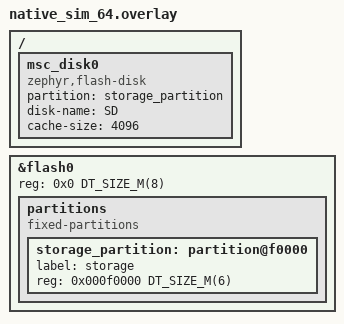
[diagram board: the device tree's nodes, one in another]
/*
 * Copyright (c) 2023 Nordic Semiconductor ASA
 * Copyright (c) 2025 Muhammad Waleed Badar
 * Copyright 2026 NXP
 *
 * SPDX-License-Identifier: Apache-2.0
 */

/delete-node/ &storage_partition;

&flash0 {
	/* Increase flash so we have room for a FAT volume with an MJPEG sample */
	reg = <0x0 DT_SIZE_M(8)>;

	partitions {
		compatible = "fixed-partitions";
		#address-cells = <1>;
		#size-cells = <1>;

		storage_partition: partition@f0000 {
			label = "storage";
			reg = <0x000f0000 DT_SIZE_M(6)>;
		};
	};
};

/ {
	msc_disk0 {
		status = "okay";
		compatible = "zephyr,flash-disk";
		partition = <&storage_partition>;
		disk-name = "SD";
		cache-size = <4096>;
	};
};
